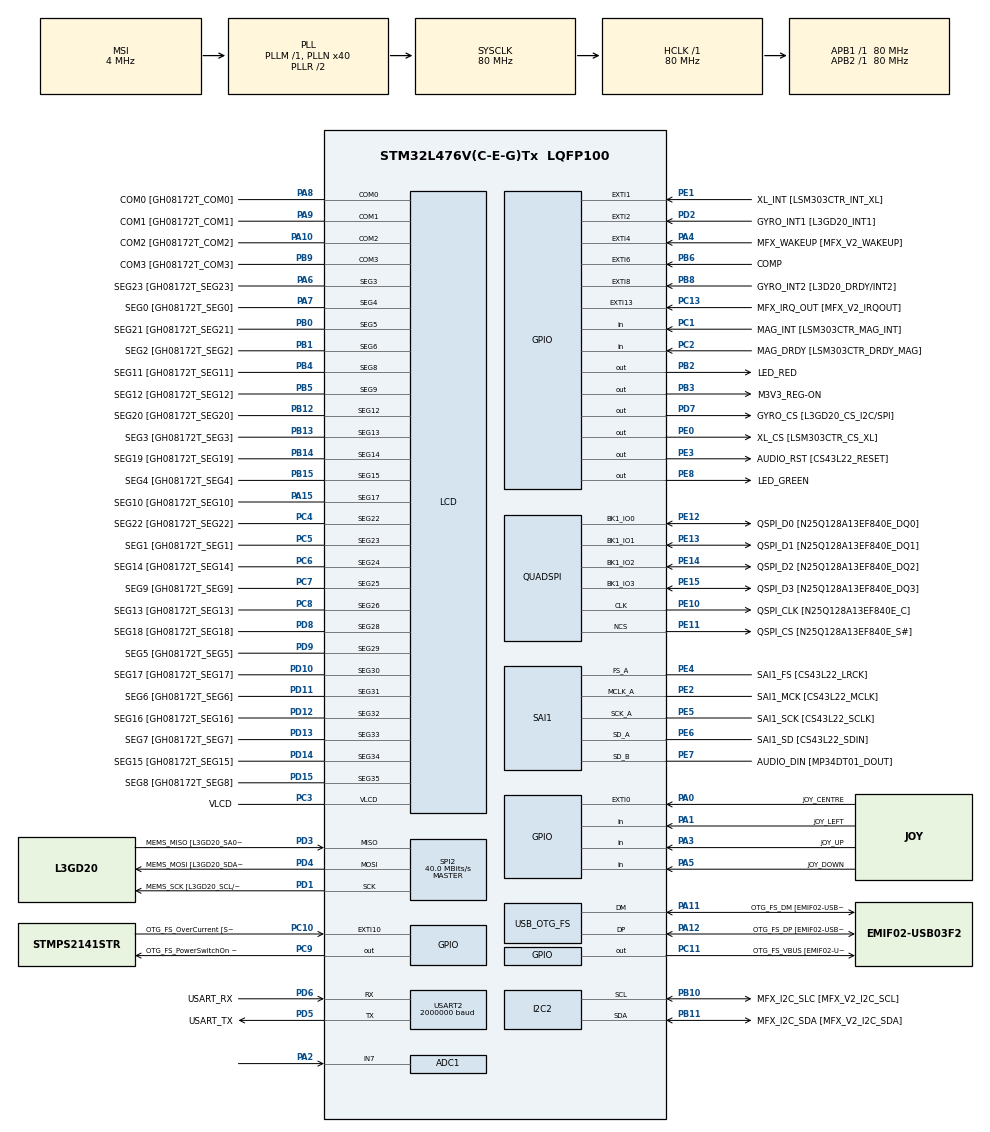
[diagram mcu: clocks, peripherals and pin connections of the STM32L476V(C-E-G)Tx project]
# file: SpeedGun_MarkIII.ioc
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PD12.GPIO_Label=SEG16 [GH08172T_SEG16]
PC10.GPIO_PuPd=GPIO_NOPULL
PA10.GPIO_PuPd=GPIO_NOPULL
PA3.GPIO_PuPd=GPIO_PULLDOWN
SAI1.Instance-SAI_A_MasterWithClock=SAI$Index_Block_A
PE10.GPIO_PuPd=GPIO_NOPULL
PD10.GPIO_PuPd=GPIO_NOPULL
PA15\ (JTDI).Signal=LCD_SEG17
PB3\ (JTDO-TRACESWO).GPIO_ModeDefaultOutputPP=GPIO_MODE_OUTPUT_PP
PA6.GPIO_Mode=GPIO_MODE_AF_PP
PE13.GPIO_Mode=GPIO_MODE_AF_PP
PD13.GPIO_Mode=GPIO_MODE_AF_PP
PD7.GPIO_PuPd=GPIO_NOPULL
PB13.GPIO_Mode=GPIO_MODE_AF_PP
RCC.APB2TimFreq_Value=80000000
PC4.GPIO_Mode=GPIO_MODE_AF_PP
PB6.Signal=GPXTI6
PC7.Signal=LCD_SEG25
PD8.Signal=LCD_SEG28
PE1.Signal=GPXTI1
USB_OTG_FS.phy_itface=HCD_PHY_EMBEDDED
PC1.GPIO_PuPd=GPIO_NOPULL
PD1.GPIO_Label=MEMS_SCK [L3GD20_SCL/SPC]
PB12.GPIO_Label=SEG20 [GH08172T_SEG20]
PC4.GPIO_Label=SEG22 [GH08172T_SEG22]
PB1.GPIO_Speed=GPIO_SPEED_FREQ_LOW
PE9.Signal=SAI1_FS_B
PD1.GPIO_Speed=GPIO_SPEED_FREQ_VERY_HIGH
PB14.Mode=SEG14
PB1.GPIO_Label=SEG2 [GH08172T_SEG2]
PE4.GPIO_Label=SAI1_FS [CS43L22_LRCK]
PD14.GPIO_PuPd=GPIO_NOPULL
PA8.Signal=LCD_COM0
PE13.Mode=Single Bank
PB2.GPIO_PuPd=GPIO_NOPULL
PA0.Signal=GPXTI0
PE9.GPIO_Mode=GPIO_MODE_AF_PP
PD15.Mode=SEG35
Mcu.Package=LQFP100
PE2.GPIO_Mode=GPIO_MODE_AF_PP
PB9.Signal=LCD_COM3
PB1.Signal=LCD_SEG6
PB14.GPIO_PuPd=GPIO_NOPULL
SPI2.Mode=SPI_MODE_MASTER
PD12.Signal=LCD_SEG32
PA10.Signal=LCD_COM2
PB9.GPIO_PuPd=GPIO_NOPULL
PE12.GPIO_Label=QSPI_D0 [N25Q128A13EF840E_DQ0]
PE12.GPIO_Speed=GPIO_SPEED_FREQ_VERY_HIGH
PC8.GPIO_Speed=GPIO_SPEED_FREQ_LOW
PB5.GPIO_Speed=GPIO_SPEED_FREQ_LOW
PE8.GPIO_Speed=GPIO_SPEED_FREQ_VERY_HIGH
RCC.APB1TimFreq_Value=80000000
PD5.GPIO_Speed=GPIO_SPEED_FREQ_VERY_HIGH
PB13.Mode=SEG13
PD3.GPIO_PuPd=GPIO_NOPULL
PE6.GPIO_PuPd=GPIO_NOPULL
PA4.GPIO_Label=MFX_WAKEUP [MFX_V2_WAKEUP]
PA8.GPIO_Speed=GPIO_SPEED_FREQ_LOW
PD15.Signal=LCD_SEG35
PC8.GPIO_Mode=GPIO_MODE_AF_PP
PE12.Mode=Single Bank
PB5.GPIO_Mode=GPIO_MODE_AF_PP
TIM3.AutoReloadPreload=TIM_AUTORELOAD_PRELOAD_ENABLE
SAI1.MClockEnable-SAI_A_MasterWithClock=SAI_MASTERCLOCK_ENABLE
PC13.Signal=GPXTI13
PD3.Signal=SPI2_MISO
PC2.Signal=GPIO_Input
PD6.Mode=Asynchronous
USART2.BaudRate=2000000
PD10.Signal=LCD_SEG30
PB8.GPIO_Label=GYRO_INT2 [L3D20_DRDY/INT2]
PB10.GPIO_Mode=GPIO_MODE_AF_OD
PA8.GPIO_Label=COM0 [GH08172T_COM0]
PE8.GPIO_Label=LED_GREEN
PB1.GPIO_Mode=GPIO_MODE_AF_PP
PB13.GPIO_Speed=GPIO_SPEED_FREQ_LOW
PA4.GPIO_ModeDefaultEXTI=GPIO_MODE_EVT_RISING
PD8.Mode=SEG28
SAI1.VirtualMode-SAI_A_MasterWithClock=VM_MASTER
PB14.Signal=LCD_SEG14
PE2.GPIO_PuPd=GPIO_NOPULL
PA5.Signal=GPIO_Input
PE1.GPIO_Label=XL_INT [LSM303CTR_INT_XL]
PD1.Mode=Full_Duplex_Master
NVIC.TIM3_IRQn=true\:0\:0\:true\:false\:true\:true\:true
PB13.GPIO_PuPd=GPIO_NOPULL
PE14.Signal=QUADSPI_BK1_IO2
PE6.Mode=SAI_A_MasterWithClock
PB15.GPIO_Label=SEG4 [GH08172T_SEG4]
PD4.GPIO_Speed=GPIO_SPEED_FREQ_VERY_HIGH
PA1.GPIO_Label=JOY_LEFT
PC9.GPIO_PuPd=GPIO_NOPULL
PE3.GPIO_PuPd=GPIO_NOPULL
PA15\ (JTDI).GPIO_PuPd=GPIO_NOPULL
PC7.GPIO_Label=SEG9 [GH08172T_SEG9]
PC8.Mode=SEG26
PC8.GPIO_PuPd=GPIO_NOPULL
PA13\ (JTMS-SWDIO).Mode=Serial_Wire
ADC1.master=1
PA5.GPIO_Label=JOY_DOWN
PB5.GPIO_PuPd=GPIO_NOPULL
PE5.GPIO_Label=SAI1_SCK [CS43L22_SCLK]
ProjectManager.HeapSize=0x200
PB1.Mode=SEG6
PD8.GPIO_Speed=GPIO_SPEED_FREQ_LOW
USB_HOST.USBH_HandleTypeDef=hUsbHostFS
NVIC.PriorityGroup=NVIC_PRIORITYGROUP_2
PC5.GPIO_Speed=GPIO_SPEED_FREQ_LOW
PE15.GPIO_Speed=GPIO_SPEED_FREQ_VERY_HIGH
PE3.Signal=GPIO_Output
PB3\ (JTDO-TRACESWO).GPIO_Speed=GPIO_SPEED_FREQ_LOW
PD2.Signal=GPXTI2
PD14.GPIO_Mode=GPIO_MODE_AF_PP
PB4\ (NJTRST).GPIO_PuPd=GPIO_NOPULL
Mcu.Family=STM32L4
PA6.Mode=SEG3
PH0-OSC_IN\ (PH0).Signal=RCC_OSC_IN
PE11.GPIO_Label=QSPI_CS [N25Q128A13EF840E_S\#]
PB2.GPIO_Speed=GPIO_SPEED_FREQ_VERY_HIGH
PA7.GPIO_Mode=GPIO_MODE_AF_PP
PA0.GPIO_Label=JOY_CENTRE
PE2.GPIO_Speed=GPIO_SPEED_FREQ_VERY_HIGH
PD9.GPIO_Speed=GPIO_SPEED_FREQ_LOW
PA11.Mode=Host_Only
PB4\ (NJTRST).GPIO_Speed=GPIO_SPEED_FREQ_LOW
PB13.GPIO_Label=SEG3 [GH08172T_SEG3]
PD8.GPIO_PuPd=GPIO_NOPULL
PB15.Signal=LCD_SEG15
PD9.Mode=SEG29
PB3\ (JTDO-TRACESWO).Signal=GPIO_Output
PD13.Signal=LCD_SEG33
PC11.GPIO_PuPd=GPIO_NOPULL
SAI1.VirtualMode-SAI_B_SyncSlave=VM_SLAVE
PE11.GPIO_PuPd=GPIO_NOPULL
PB1.GPIO_PuPd=GPIO_NOPULL
TIM3.Period=99
USB_HOST0.BSP.ip=GPIO
PD4.GPIO_Mode=GPIO_MODE_AF_PP
PD5.Mode=Asynchronous
PA9.GPIO_Mode=GPIO_MODE_AF_PP
PH1-OSC_OUT\ (PH1).Mode=HSE-External-Oscillator
RCC.HSE_VALUE=8000000
PA4.GPIO_PuPd=GPIO_NOPULL
PE13.GPIO_PuPd=GPIO_NOPULL
PC10.GPIO_ModeDefaultEXTI=GPIO_MODE_EVT_RISING
PC4.GPIO_Speed=GPIO_SPEED_FREQ_LOW
PA6.GPIO_PuPd=GPIO_NOPULL
PD14.Mode=SEG34
TIM3.Prescaler=39
PC11.GPIO_Label=OTG_FS_VBUS [EMIF02-USB03F2_Vbus]
PB5.Mode=SEG9
PC13.GPIO_PuPd=GPIO_NOPULL
PC7.GPIO_Mode=GPIO_MODE_AF_PP
PB7.Signal=COMP2_INM
PA15\ (JTDI).GPIO_Mode=GPIO_MODE_AF_PP
PD10.GPIO_Speed=GPIO_SPEED_FREQ_LOW
PD6.GPIO_Mode=GPIO_MODE_AF_PP
PB12.GPIO_Mode=GPIO_MODE_AF_PP
PD13.GPIO_Label=SEG7 [GH08172T_SEG7]
PA6.Signal=LCD_SEG3
PB12.Mode=SEG12
PB0.GPIO_Mode=GPIO_MODE_AF_PP
PB15.GPIO_PuPd=GPIO_NOPULL
PD5.GPIO_Label=USART_TX
NVIC.OTG_FS_IRQn=true\:0\:0\:false\:false\:true\:true\:true
PA10.GPIO_Speed=GPIO_SPEED_FREQ_LOW
USB_HOST0.BSP.name=Drive_VBUS_FS
SH.ADCx_IN1.0=ADC1_IN1
PB5.GPIO_Label=SEG12 [GH08172T_SEG12]
PE8.GPIO_ModeDefaultOutputPP=GPIO_MODE_OUTPUT_PP
PC5.Signal=LCD_SEG23
PD3.GPIO_Label=MEMS_MISO [L3GD20_SA0/SDO]
PE14.GPIO_Mode=GPIO_MODE_AF_PP
RCC.MSIAutoCalibration=DISABLED
PE7.Signal=SAI1_SD_B
PD6.Signal=USART2_RX
PE2.GPIO_Label=SAI1_MCK [CS43L22_MCLK]
PB9.GPIO_FM9=__NULL
VP_TIM3_VS_ClockSourceINT.Mode=Internal
PA12.GPIO_Speed=GPIO_SPEED_FREQ_VERY_HIGH
PA3.Signal=GPIO_Input
PE0.GPIO_PuPd=GPIO_NOPULL
RCC.MSI_VALUE=4000000
PA14\ (JTCK-SWCLK).Mode=Serial_Wire
PB4\ (NJTRST).GPIO_Mode=GPIO_MODE_AF_PP
PE0.GPIO_ModeDefaultOutputPP=GPIO_MODE_OUTPUT_PP
PD15.GPIO_Label=SEG8 [GH08172T_SEG8]
PA10.Mode=1/4 Duty Cycle
PC9.GPIO_Label=OTG_FS_PowerSwitchOn [STMPS2141STR_EN]
PC11.Signal=GPIO_Output
PC8.Signal=LCD_SEG26
USB_HOST0.BSP.solution=PC9
PE14.GPIO_Label=QSPI_D2 [N25Q128A13EF840E_DQ2]
PD9.Signal=LCD_SEG29
PA9.GPIO_PuPd=GPIO_NOPULL
PA12.GPIO_Label=OTG_FS_DP [EMIF02-USB03F2_D+out]
PH1-OSC_OUT\ (PH1).Signal=RCC_OSC_OUT
PD8.GPIO_Label=SEG18 [GH08172T_SEG18]
PB0.GPIO_Speed=GPIO_SPEED_FREQ_LOW
PD4.GPIO_PuPd=GPIO_NOPULL
PA9.Mode=1/4 Duty Cycle
PB10.GPIO_Label=MFX_I2C_SLC [MFX_V2_I2C_SCL]
PA3.GPIO_Mode=GPIO_MODE_INPUT
PB9.Mode=1/4 Duty Cycle
RCC.USBFreq_Value=48000000
PD10.GPIO_Label=SEG17 [GH08172T_SEG17]
PA1.Signal=GPIO_Input
PA7.GPIO_PuPd=GPIO_NOPULL
PE10.GPIO_Mode=GPIO_MODE_AF_PP
board=STM32L476G-DISCO
PD13.GPIO_Speed=GPIO_SPEED_FREQ_LOW
PC7.GPIO_Speed=GPIO_SPEED_FREQ_LOW
RCC.VCOOutputFreq_Value=160000000
PB15.Mode=SEG15
PA13\ (JTMS-SWDIO).GPIO_Label=SWDIO
PE5.Mode=SAI_A_MasterWithClock
PC9.GPIO_ModeDefaultOutputPP=GPIO_MODE_OUTPUT_PP
RCC.ADCFreq_Value=12000000
PC1.GPIO_Label=MAG_INT [LSM303CTR_MAG_INT]
PE11.GPIO_Mode=GPIO_MODE_AF_PP
PD5.GPIO_PuPd=GPIO_PULLUP
PE14.GPIO_PuPd=GPIO_NOPULL
PA15\ (JTDI).GPIO_Label=SEG10 [GH08172T_SEG10]
PE0.Signal=GPIO_Output
PE7.GPIO_Label=AUDIO_DIN [MP34DT01_DOUT]
PE12.Signal=QUADSPI_BK1_IO0
PE12.GPIO_Mode=GPIO_MODE_AF_PP
RCC.SYSCLKFreq_VALUE=80000000
VP_USB_HOST_VS_USB_HOST_CDC_FS.Mode=CDC_FS
PC14-OSC32_IN\ (PC14).Signal=RCC_OSC32_IN
NVIC.EXTI9_5_IRQn=true\:1\:0\:true\:false\:true\:true\:true
PB2.GPIO_Label=LED_RED
PE15.GPIO_PuPd=GPIO_NOPULL
PD11.Mode=SEG31
PD3.GPIO_Mode=GPIO_MODE_AF_PP
RCC.HSI_VALUE=16000000
PA8.GPIO_PuPd=GPIO_NOPULL
RCC.PLLN=40
PE5.GPIO_Speed=GPIO_SPEED_FREQ_VERY_HIGH
PA9.GPIO_Speed=GPIO_SPEED_FREQ_LOW
PA5.GPIO_Mode=GPIO_MODE_INPUT
PD6.GPIO_Speed=GPIO_SPEED_FREQ_VERY_HIGH
PB14.GPIO_Mode=GPIO_MODE_AF_PP
PD7.GPIO_ModeDefaultOutputPP=GPIO_MODE_OUTPUT_PP
PB12.Signal=LCD_SEG12
PB0.GPIO_PuPd=GPIO_NOPULL
PA3.GPIO_Label=JOY_UP
PD6.GPIO_PuPd=GPIO_PULLUP
USB_HOST0.BSP.instance=PC9
PB4\ (NJTRST).Signal=LCD_SEG8
PA11.GPIO_Speed=GPIO_SPEED_FREQ_VERY_HIGH
NVIC.ADC1_2_IRQn=true\:0\:1\:true\:false\:true\:true\:true
PE15.GPIO_Mode=GPIO_MODE_AF_PP
PD1.GPIO_Mode=GPIO_MODE_AF_PP
PB15.GPIO_Mode=GPIO_MODE_AF_PP
PD15.GPIO_Mode=GPIO_MODE_AF_PP
PE14.GPIO_Speed=GPIO_SPEED_FREQ_VERY_HIGH
SPI2.VirtualType=VM_MASTER
PB10.Mode=I2C
PA8.GPIO_Mode=GPIO_MODE_AF_PP
PB14.GPIO_Label=SEG19 [GH08172T_SEG19]
PE8.GPIO_PuPd=GPIO_NOPULL
PC6.GPIO_Label=SEG14 [GH08172T_SEG14]
PA6.GPIO_Label=SEG23 [GH08172T_SEG23]
PB6.GPIO_Label=COMP
PC5.Mode=SEG23
PB13.Signal=LCD_SEG13
PD3.GPIO_Speed=GPIO_SPEED_FREQ_VERY_HIGH
PD6.GPIO_Label=USART_RX
PE6.GPIO_Label=SAI1_SD [CS43L22_SDIN]
PC3.GPIO_Speed=GPIO_SPEED_FREQ_LOW
RCC.SYSCLKSource=RCC_SYSCLKSOURCE_PLLCLK
PB11.GPIO_Speed=GPIO_SPEED_FREQ_VERY_HIGH
PA14\ (JTCK-SWCLK).Signal=SYS_JTCK-SWCLK
PD14.GPIO_Speed=GPIO_SPEED_FREQ_LOW
PA15\ (JTDI).Mode=SEG17
PE2.Mode=SAI_A_MasterWithClock
PD4.Signal=SPI2_MOSI
PC3.Signal=LCD_VLCD
PE5.Signal=SAI1_SCK_A
PA1.GPIO_PuPd=GPIO_PULLDOWN
PD2.GPIO_ModeDefaultEXTI=GPIO_MODE_EVT_RISING
PB2.Signal=GPIO_Output
PA5.GPIO_PuPd=GPIO_PULLDOWN
PD11.GPIO_Mode=GPIO_MODE_AF_PP
SPI2.CalculateBaudRate=40.0 MBits/s
PC11.GPIO_Speed=GPIO_SPEED_FREQ_LOW
PD5.GPIO_Mode=GPIO_MODE_AF_PP
PE2.Signal=SAI1_MCLK_A
PD3.Mode=Full_Duplex_Master
PE10.Signal=QUADSPI_CLK
PC6.GPIO_PuPd=GPIO_NOPULL
PC2.GPIO_Mode=GPIO_MODE_INPUT
PD4.Mode=Full_Duplex_Master
PA6.GPIO_Speed=GPIO_SPEED_FREQ_LOW
PB11.GPIO_Mode=GPIO_MODE_AF_OD
PA13\ (JTMS-SWDIO).Signal=SYS_JTMS-SWDIO
PA12.GPIO_PuPd=GPIO_NOPULL
PE10.GPIO_Label=QSPI_CLK [N25Q128A13EF840E_C]
PD9.GPIO_PuPd=GPIO_NOPULL
PB2.GPIO_ModeDefaultOutputPP=GPIO_MODE_OUTPUT_PP
PH0-OSC_IN\ (PH0).Mode=HSE-External-Oscillator
PE6.GPIO_Speed=GPIO_SPEED_FREQ_VERY_HIGH
PC6.GPIO_Speed=GPIO_SPEED_FREQ_LOW
PC4.Mode=SEG22
PE12.GPIO_PuPd=GPIO_NOPULL
PD8.GPIO_Mode=GPIO_MODE_AF_PP
PD9.GPIO_Label=SEG5 [GH08172T_SEG5]
PA1.GPIO_Mode=GPIO_MODE_INPUT
PD2.GPIO_PuPd=GPIO_NOPULL
PE11.GPIO_Speed=GPIO_SPEED_FREQ_VERY_HIGH
PA9.GPIO_Label=COM1 [GH08172T_COM1]
PB10.GPIO_PuPdOD=GPIO_PULLUP
PB11.GPIO_PuPdOD=GPIO_PULLUP
PD9.GPIO_Mode=GPIO_MODE_AF_PP
PB8.GPIO_PuPd=GPIO_NOPULL
PE10.Mode=Single Bank
PC6.Signal=LCD_SEG24
PB11.GPIO_Label=MFX_I2C_SDA [MFX_V2_I2C_SDA]
PC9.PinState=GPIO_PIN_SET
PD7.Signal=GPIO_Output
PD1.Signal=SPI2_SCK
PA11.GPIO_Label=OTG_FS_DM [EMIF02-USB03F2_D-out]
PE1.GPIO_PuPd=GPIO_NOPULL
PD1.GPIO_PuPd=GPIO_NOPULL
PC0.Signal=ADCx_IN1
PB3\ (JTDO-TRACESWO).GPIO_PuPd=GPIO_NOPULL
PE0.GPIO_Speed=GPIO_SPEED_FREQ_LOW
USB_HOST0.BSP.STBoard=false
PB11.Mode=I2C
PB14.GPIO_Speed=GPIO_SPEED_FREQ_LOW
SH.ADCx_IN7.0=ADC1_IN7,IN7-Single-Ended
PC6.Mode=SEG24
PD11.GPIO_Speed=GPIO_SPEED_FREQ_LOW
PA9.Signal=LCD_COM1
PC7.GPIO_PuPd=GPIO_NOPULL
PE9.GPIO_Label=AUDIO_CLK [MP34DT01_CLK]
PB10.Signal=I2C2_SCL
PA15\ (JTDI).GPIO_Speed=GPIO_SPEED_FREQ_LOW
USB_HOST.VirtualModeFS=Cdc
PA7.GPIO_Speed=GPIO_SPEED_FREQ_LOW
PE7.GPIO_Speed=GPIO_SPEED_FREQ_VERY_HIGH
PE15.Signal=QUADSPI_BK1_IO3
PE8.Signal=GPIO_Output
PC6.GPIO_Mode=GPIO_MODE_AF_PP
PC11.GPIO_ModeDefaultOutputPP=GPIO_MODE_OUTPUT_PP
PB4\ (NJTRST).Mode=SEG8
PE4.GPIO_PuPd=GPIO_NOPULL
PA4.Signal=GPXTI4
ADC1.SamplingTime-1\#ChannelRegularConversion=ADC_SAMPLETIME_24CYCLES_5
PB5.Signal=LCD_SEG9
PE13.GPIO_Label=QSPI_D1 [N25Q128A13EF840E_DQ1]
PD12.Mode=SEG32
PE3.GPIO_ModeDefaultOutputPP=GPIO_MODE_OUTPUT_PP
PE3.GPIO_Speed=GPIO_SPEED_FREQ_HIGH
PD11.Signal=LCD_SEG31
ADC1.Rank-1\#ChannelRegularConversion=1
PA11.Signal=USB_OTG_FS_DM
PC5.GPIO_Mode=GPIO_MODE_AF_PP
PC9.GPIO_Speed=GPIO_SPEED_FREQ_LOW
PC3.GPIO_Label=VLCD
PA8.Mode=1/4 Duty Cycle
PB4\ (NJTRST).GPIO_Label=SEG11 [GH08172T_SEG11]
PB12.GPIO_PuPd=GPIO_NOPULL
PB0.Signal=LCD_SEG5
USB_HOST0.BSP.mode=Output
PC1.Signal=GPIO_Input
PD2.GPIO_Label=GYRO_INT1 [L3GD20_INT1]
PE15.Mode=Single Bank
PC3.Mode=1/4 Duty Cycle
PC3.GPIO_Mode=GPIO_MODE_AF_PP
PE7.GPIO_PuPd=GPIO_NOPULL
RCC.CortexFreq_Value=80000000
PB10.GPIO_Speed=GPIO_SPEED_FREQ_VERY_HIGH
PD15.GPIO_Speed=GPIO_SPEED_FREQ_LOW
PC10.Signal=GPXTI10
I2C2.Timing=0x10909CEC
PE9.GPIO_Speed=GPIO_SPEED_FREQ_LOW
PB0.GPIO_Label=SEG21 [GH08172T_SEG21]
PA11.GPIO_PuPd=GPIO_NOPULL
PC13.GPIO_Label=MFX_IRQ_OUT [MFX_V2_IRQOUT]
PB11.Signal=I2C2_SDA
ProjectManager.StackSize=0x400
PD11.GPIO_PuPd=GPIO_NOPULL
PA12.Signal=USB_OTG_FS_DP
PB8.GPIO_ModeDefaultEXTI=GPIO_MODE_EVT_RISING
PE11.Mode=Single Bank
PE5.GPIO_PuPd=GPIO_NOPULL
PD11.GPIO_Label=SEG6 [GH08172T_SEG6]
RCC.HCLKFreq_Value=80000000
PD10.Mode=SEG30
RCC.AHBFreq_Value=80000000
SPI2.BaudRatePrescaler=SPI_BAUDRATEPRESCALER_2
PC1.GPIO_Mode=GPIO_MODE_INPUT
USART2.VirtualMode-Asynchronous=VM_ASYNC
PD7.GPIO_Speed=GPIO_SPEED_FREQ_VERY_HIGH
PE13.Signal=QUADSPI_BK1_IO1
PE4.GPIO_Speed=GPIO_SPEED_FREQ_VERY_HIGH
PA10.GPIO_Label=COM2 [GH08172T_COM2]
PE4.Mode=SAI_A_MasterWithClock
PE10.GPIO_Speed=GPIO_SPEED_FREQ_VERY_HIGH
USB_HOST0.BSP.i2creg=0
PE4.Signal=SAI1_FS_A
PD12.GPIO_Mode=GPIO_MODE_AF_PP
PD7.GPIO_Label=GYRO_CS [L3GD20_CS_I2C/SPI]
USB_HOST0.BSP.i2caddr=0
PD15.GPIO_PuPd=GPIO_NOPULL
USB_OTG_FS.VirtualMode=Host_Only
ADC1.OffsetNumber-1\#ChannelRegularConversion=ADC_OFFSET_NONE
PE0.GPIO_Label=XL_CS [LSM303CTR_CS_XL]
PB9.GPIO_Speed=GPIO_SPEED_FREQ_LOW
SAI1.Synchro-SAI_B_SyncSlave=SAI_SYNCHRONOUS
SPI2.Direction=SPI_DIRECTION_2LINES
PC2.GPIO_Label=MAG_DRDY [LSM303CTR_DRDY_MAG]
RCC.PLLSAI1R=RCC_PLLR_DIV8
RCC.PLLSAI1N=24
PD12.GPIO_Speed=GPIO_SPEED_FREQ_LOW
PA7.Mode=SEG4
PB9.GPIO_Label=COM3 [GH08172T_COM3]
PC10.GPIO_Label=OTG_FS_OverCurrent [STMPS2141STR_FAULT]
PE6.GPIO_Mode=GPIO_MODE_AF_PP
PC4.GPIO_PuPd=GPIO_NOPULL
PC4.Signal=LCD_SEG22
USB_HOST.BSP.number=1
PE5.GPIO_Mode=GPIO_MODE_AF_PP
PC15-OSC32_OUT\ (PC15).Signal=RCC_OSC32_OUT
PD5.Signal=USART2_TX
PA14\ (JTCK-SWCLK).GPIO_Label=SWCLK
PB3\ (JTDO-TRACESWO).GPIO_Label=M3V3_REG-ON
PE1.GPIO_ModeDefaultEXTI=GPIO_MODE_EVT_RISING
PC5.GPIO_PuPd=GPIO_NOPULL
NVIC.USART2_IRQn=true\:2\:0\:true\:false\:true\:true\:true
PA10.GPIO_Mode=GPIO_MODE_AF_PP
PD10.GPIO_Mode=GPIO_MODE_AF_PP
PC8.GPIO_Label=SEG13 [GH08172T_SEG13]
PE4.GPIO_Mode=GPIO_MODE_AF_PP
PE15.GPIO_Label=QSPI_D3 [N25Q128A13EF840E_DQ3]
ProjectManager.TargetToolchain=STM32CubeIDE
ADC1.Channel-1\#ChannelRegularConversion=ADC_CHANNEL_7
PD13.Mode=SEG33
PE11.Signal=QUADSPI_NCS
RCC.LSE_VALUE=32768
PE7.GPIO_Mode=GPIO_MODE_AF_PP
PB12.GPIO_Speed=GPIO_SPEED_FREQ_LOW
PB0.Mode=SEG5
PB9.GPIO_Mode=GPIO_MODE_AF_PP
PA12.GPIO_Mode=GPIO_MODE_AF_PP
RCC.APB2Freq_Value=80000000
USB_HOST0.BSP.api=Unknown
PD4.GPIO_Label=MEMS_MOSI [L3GD20_SDA/SDI/SDO]
PE14.Mode=Single Bank
PB15.GPIO_Speed=GPIO_SPEED_FREQ_LOW
PD13.GPIO_PuPd=GPIO_NOPULL
PD14.GPIO_Label=SEG15 [GH08172T_SEG15]
PC2.GPIO_PuPd=GPIO_NOPULL
PE6.Signal=SAI1_SD_A
Mcu.Name=STM32L476V(C-E-G)Tx
PA2.Signal=ADCx_IN7
PD14.Signal=LCD_SEG34
NVIC.EXTI0_IRQn=true\:2\:0\:true\:false\:true\:true\:true
PE7.Mode=SAI_B_SyncSlave
PA7.GPIO_Label=SEG0 [GH08172T_SEG0]
PA12.Mode=Host_Only
PC13.GPIO_ModeDefaultEXTI=GPIO_MODE_EVT_RISING
PC5.GPIO_Label=SEG1 [GH08172T_SEG1]
SAI1.Instance-SAI_B_SyncSlave=SAI$Index_Block_B
ADC1.NbrOfConversionFlag=1
PE13.GPIO_Speed=GPIO_SPEED_FREQ_VERY_HIGH
PB8.Signal=GPXTI8
PE3.GPIO_Label=AUDIO_RST [CS43L22_RESET]
PC9.Signal=GPIO_Output
TIM3.TIM_MasterOutputTrigger=TIM_TRGO_UPDATE
PC7.Mode=SEG25
PA11.GPIO_Mode=GPIO_MODE_AF_PP
RCC.APB1Freq_Value=80000000
PD12.GPIO_PuPd=GPIO_NOPULL
PC3.GPIO_PuPd=GPIO_NOPULL
PA7.Signal=LCD_SEG4
PE9.GPIO_PuPd=GPIO_NOPULL

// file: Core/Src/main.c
/* USER CODE BEGIN Header */
/**
 ******************************************************************************
 * @file           : main.c
 * @brief          : Main program body
 ******************************************************************************
 * @attention
 *
 * <h2><center>&copy; Copyright (c) 2020 STMicroelectronics.
 * All rights reserved.</center></h2>
 *
 * This software component is licensed by ST under Ultimate Liberty license
 * SLA0044, the "License"; You may not use this file except in compliance with
 * the License. You may obtain a copy of the License at:
 *                             www.st.com/SLA0044
 *
 ******************************************************************************
 */
/* USER CODE END Header */
#include "main.h"
#include "adc.h"
#include "i2c.h"
#include "lcd.h"
#include "quadspi.h"
#include "sai.h"
#include "spi.h"
#include "tim.h"
#include "usart.h"
#include "usb_host.h"
#include "gpio.h"

/* USER CODE BEGIN Includes */
#include "stdio.h"
#include "display.h"
#include "communication.h"
#include "adc.h"
#include "arm_math.h"
#include "arm_const_structs.h"
/* USER CODE END Includes */

/* USER CODE BEGIN PV */
int Value_1;
int Value_2[5000];
int flag_adc = 0;
int counter_adc = 1;
int counter_timer = 0;
int counter_comp = 0;
int freq_comp = 0;
/* USER CODE END PV */

void SystemClock_Config(void);
void MX_USB_HOST_Process(void);

int main(void) {
	/* USER CODE BEGIN 1 */
	//unsigned char uRx_Data = 0;
	/* USER CODE END 1 */

	/* MCU Configuration--------------------------------------------------------*/

	/* Reset of all peripherals, Initializes the Flash interface and the Systick. */
	HAL_Init();

	/* Configure the system clock */
	SystemClock_Config();

	/* Initialize all configured peripherals */
	MX_GPIO_Init();
	MX_I2C2_Init();
	MX_LCD_Init();
	MX_QUADSPI_Init();
	MX_SAI1_Init();
	MX_SPI2_Init();
	MX_USART2_UART_Init();
	MX_USB_HOST_Init();
	MX_TIM3_Init();
	MX_ADC1_Init();
	/* USER CODE BEGIN 2 */
	HAL_ADCEx_Calibration_Start(&hadc1, ADC_SINGLE_ENDED); //adc calibration
	BSP_LCD_GLASS_Init();
	HAL_TIM_Base_Start_IT(&htim3);

	//user interface
	//gui();
	/* USER CODE END 2 */

	/* Infinite loop */
	while (1) {
		MX_USB_HOST_Process();

		/* USER CODE BEGIN 3 */
		if (!flag_adc) {
			int freq_fft = dfft();
			for (int i = 0; i < 4096; i++) {
//				printf("%d\n", Value_2[i]);
				flag_adc = 1;
			}
			printf("freq:%dHz speed:%dkmph\n", freq_fft * 8014 / 8000,
					freq_fft * 8014 / 8000 * 513 / 10000);
		}
		//comp
//		printf("freq:%dHz speed:%dkmph\n", freq_comp, freq_comp * 513 / 10000);
	}
	/* USER CODE END 3 */
}

void SystemClock_Config(void) {
	RCC_OscInitTypeDef RCC_OscInitStruct = { 0 };
	RCC_ClkInitTypeDef RCC_ClkInitStruct = { 0 };
	RCC_PeriphCLKInitTypeDef PeriphClkInit = { 0 };

	/** Initializes the RCC Oscillators according to the specified parameters
	 * in the RCC_OscInitTypeDef structure.
	 */
	RCC_OscInitStruct.OscillatorType = RCC_OSCILLATORTYPE_LSI
			| RCC_OSCILLATORTYPE_MSI;
	RCC_OscInitStruct.LSIState = RCC_LSI_ON;
	RCC_OscInitStruct.MSIState = RCC_MSI_ON;
	RCC_OscInitStruct.MSICalibrationValue = 0;
	RCC_OscInitStruct.MSIClockRange = RCC_MSIRANGE_6;
	RCC_OscInitStruct.PLL.PLLState = RCC_PLL_ON;
	RCC_OscInitStruct.PLL.PLLSource = RCC_PLLSOURCE_MSI;
	RCC_OscInitStruct.PLL.PLLM = 1;
	RCC_OscInitStruct.PLL.PLLN = 40;
	RCC_OscInitStruct.PLL.PLLP = RCC_PLLP_DIV7;
	RCC_OscInitStruct.PLL.PLLQ = RCC_PLLQ_DIV2;
	RCC_OscInitStruct.PLL.PLLR = RCC_PLLR_DIV2;
	if (HAL_RCC_OscConfig(&RCC_OscInitStruct) != HAL_OK) {
		Error_Handler();
	}
	/** Initializes the CPU, AHB and APB buses clocks
	 */
	RCC_ClkInitStruct.ClockType = RCC_CLOCKTYPE_HCLK | RCC_CLOCKTYPE_SYSCLK
			| RCC_CLOCKTYPE_PCLK1 | RCC_CLOCKTYPE_PCLK2;
	RCC_ClkInitStruct.SYSCLKSource = RCC_SYSCLKSOURCE_PLLCLK;
	RCC_ClkInitStruct.AHBCLKDivider = RCC_SYSCLK_DIV1;
	RCC_ClkInitStruct.APB1CLKDivider = RCC_HCLK_DIV1;
	RCC_ClkInitStruct.APB2CLKDivider = RCC_HCLK_DIV1;

	if (HAL_RCC_ClockConfig(&RCC_ClkInitStruct, FLASH_LATENCY_4) != HAL_OK) {
		Error_Handler();
	}
	PeriphClkInit.PeriphClockSelection = RCC_PERIPHCLK_RTC
			| RCC_PERIPHCLK_USART2 | RCC_PERIPHCLK_SAI1 | RCC_PERIPHCLK_I2C2
			| RCC_PERIPHCLK_USB | RCC_PERIPHCLK_ADC;
	PeriphClkInit.Usart2ClockSelection = RCC_USART2CLKSOURCE_PCLK1;
	PeriphClkInit.I2c2ClockSelection = RCC_I2C2CLKSOURCE_PCLK1;
	PeriphClkInit.Sai1ClockSelection = RCC_SAI1CLKSOURCE_PLLSAI1;
	PeriphClkInit.AdcClockSelection = RCC_ADCCLKSOURCE_PLLSAI1;
	PeriphClkInit.RTCClockSelection = RCC_RTCCLKSOURCE_LSI;
	PeriphClkInit.UsbClockSelection = RCC_USBCLKSOURCE_PLLSAI1;
	PeriphClkInit.PLLSAI1.PLLSAI1Source = RCC_PLLSOURCE_MSI;
	PeriphClkInit.PLLSAI1.PLLSAI1M = 1;
	PeriphClkInit.PLLSAI1.PLLSAI1N = 24;
	PeriphClkInit.PLLSAI1.PLLSAI1P = RCC_PLLP_DIV7;
	PeriphClkInit.PLLSAI1.PLLSAI1Q = RCC_PLLQ_DIV2;
	PeriphClkInit.PLLSAI1.PLLSAI1R = RCC_PLLR_DIV8;
	PeriphClkInit.PLLSAI1.PLLSAI1ClockOut = RCC_PLLSAI1_SAI1CLK
			| RCC_PLLSAI1_48M2CLK | RCC_PLLSAI1_ADC1CLK;
	if (HAL_RCCEx_PeriphCLKConfig(&PeriphClkInit) != HAL_OK) {
		Error_Handler();
	}
	/** Configure the main internal regulator output voltage
	 */
	if (HAL_PWREx_ControlVoltageScaling(PWR_REGULATOR_VOLTAGE_SCALE1)
			!= HAL_OK) {
		Error_Handler();
	}
}

/* USER CODE BEGIN 4 */
void HAL_GPIO_EXTI_Callback(uint16_t GPIO_Pin) {
//	if (COMP_Pin == GPIO_Pin) {
//		HAL_GPIO_TogglePin(LED_GREEN_GPIO_Port, LED_GREEN_Pin);
//		counter_comp++;
//		if (counter_timer >= 20010) {
//			freq_comp = counter_comp / 1;
//			counter_comp = 0;
//			counter_timer = 0;
//		}
//	}
//	return;
}
//fft
int dfft() {
	int fft_dot = 4096;
	float32_t complex[fft_dot * 2];
	float32_t output[fft_dot];
	float32_t maxvalue = 0.0f;
	uint32_t maxindex = 0;

	for (uint16_t i = 0; i < (fft_dot * 2); i += 2) {
		complex[i] = (float32_t) Value_2[i / 2];
		complex[i + 1] = 0.0f;
	}

	arm_cfft_f32(&arm_cfft_sR_f32_len4096, complex, 0, 1); // 1024 4096-------
	arm_cmplx_mag_f32(complex, output, fft_dot);
	output[0] = 0.0f; //remove DC value

	float32_t unit_freq = (float32_t) 5000 / fft_dot; //2500 is timer freq

	//remove other freq, only leave the freq with max amplitude
//    for (uint16_t i=0; i< (FREQ_MIN / unit_freq); i++)
//    {
//        output[i]=0.0f;
//    }
//    for (uint16_t i= (FREQ_MAX / unit_freq); i< fft_dot; i++)
//    {
//        output[i]=0.0f;
//    }

	arm_max_f32(output, fft_dot / 2, &maxvalue, &maxindex);
	return (int) unit_freq * maxindex * 1.95;
}
/* USER CODE END 4 */

void Error_Handler(void) {
}

/************************ (C) COPYRIGHT STMicroelectronics *****END OF FILE****/
